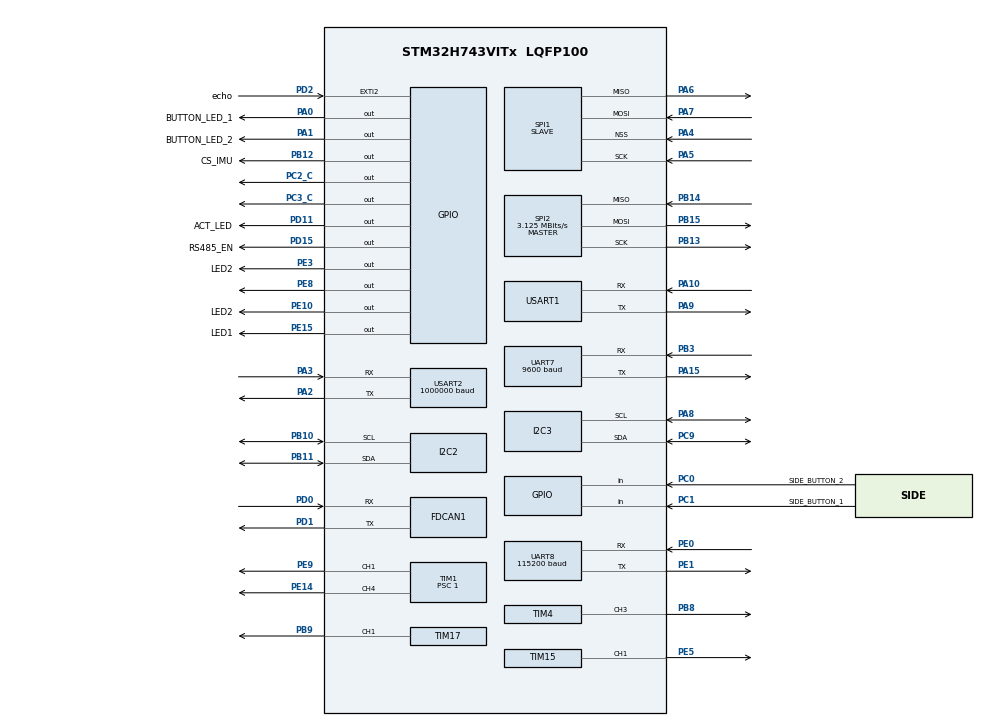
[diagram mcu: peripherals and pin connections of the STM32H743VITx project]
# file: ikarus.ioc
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CORTEX_M7.default_mode_Activation=0
Dma.MEMTOMEM.6.Direction=DMA_MEMORY_TO_MEMORY
Dma.MEMTOMEM.6.EventEnable=DISABLE
Dma.MEMTOMEM.6.FIFOMode=DMA_FIFOMODE_ENABLE
Dma.MEMTOMEM.6.FIFOThreshold=DMA_FIFO_THRESHOLD_FULL
Dma.MEMTOMEM.6.Instance=DMA2_Stream0
Dma.MEMTOMEM.6.MemBurst=DMA_MBURST_SINGLE
Dma.MEMTOMEM.6.MemDataAlignment=DMA_MDATAALIGN_BYTE
Dma.MEMTOMEM.6.MemInc=DMA_MINC_ENABLE
Dma.MEMTOMEM.6.Mode=DMA_NORMAL
Dma.MEMTOMEM.6.PeriphBurst=DMA_PBURST_SINGLE
Dma.MEMTOMEM.6.PeriphDataAlignment=DMA_PDATAALIGN_BYTE
Dma.MEMTOMEM.6.PeriphInc=DMA_PINC_ENABLE
Dma.MEMTOMEM.6.Polarity=HAL_DMAMUX_REQ_GEN_RISING
Dma.MEMTOMEM.6.Priority=DMA_PRIORITY_VERY_HIGH
Dma.MEMTOMEM.6.RequestNumber=1
Dma.MEMTOMEM.6.SignalID=NONE
Dma.MEMTOMEM.6.SyncEnable=DISABLE
Dma.MEMTOMEM.6.SyncPolarity=HAL_DMAMUX_SYNC_NO_EVENT
Dma.MEMTOMEM.6.SyncRequestNumber=1
Dma.MEMTOMEM.6.SyncSignalID=NONE
Dma.MEMTOMEM.9.Direction=DMA_MEMORY_TO_MEMORY
Dma.MEMTOMEM.9.EventEnable=DISABLE
Dma.MEMTOMEM.9.FIFOMode=DMA_FIFOMODE_ENABLE
Dma.MEMTOMEM.9.FIFOThreshold=DMA_FIFO_THRESHOLD_FULL
Dma.MEMTOMEM.9.Instance=DMA2_Stream1
Dma.MEMTOMEM.9.MemBurst=DMA_MBURST_SINGLE
Dma.MEMTOMEM.9.MemDataAlignment=DMA_MDATAALIGN_BYTE
Dma.MEMTOMEM.9.MemInc=DMA_MINC_ENABLE
Dma.MEMTOMEM.9.Mode=DMA_NORMAL
Dma.MEMTOMEM.9.PeriphBurst=DMA_PBURST_SINGLE
Dma.MEMTOMEM.9.PeriphDataAlignment=DMA_PDATAALIGN_BYTE
Dma.MEMTOMEM.9.PeriphInc=DMA_PINC_ENABLE
Dma.MEMTOMEM.9.Polarity=HAL_DMAMUX_REQ_GEN_RISING
Dma.MEMTOMEM.9.Priority=DMA_PRIORITY_HIGH
Dma.MEMTOMEM.9.RequestNumber=1
Dma.MEMTOMEM.9.SignalID=NONE
Dma.MEMTOMEM.9.SyncEnable=DISABLE
Dma.MEMTOMEM.9.SyncPolarity=HAL_DMAMUX_SYNC_NO_EVENT
Dma.MEMTOMEM.9.SyncRequestNumber=1
Dma.MEMTOMEM.9.SyncSignalID=NONE
Dma.Request0=USART1_RX
Dma.Request1=USART1_TX
Dma.Request10=UART7_RX
Dma.Request11=UART7_TX
Dma.Request12=TIM1_CH1
Dma.Request13=TIM1_CH4
Dma.Request14=TIM15_CH1
Dma.Request15=TIM4_CH3
Dma.Request2=UART8_RX
Dma.Request3=UART8_TX
Dma.Request4=USART2_RX
Dma.Request5=USART2_TX
Dma.Request6=MEMTOMEM
Dma.Request7=SPI1_RX
Dma.Request8=SPI1_TX
Dma.Request9=MEMTOMEM
Dma.SPI1_RX.7.Direction=DMA_PERIPH_TO_MEMORY
Dma.SPI1_RX.7.EventEnable=DISABLE
Dma.SPI1_RX.7.FIFOMode=DMA_FIFOMODE_DISABLE
Dma.SPI1_RX.7.Instance=DMA1_Stream6
Dma.SPI1_RX.7.MemDataAlignment=DMA_MDATAALIGN_BYTE
Dma.SPI1_RX.7.MemInc=DMA_MINC_ENABLE
Dma.SPI1_RX.7.Mode=DMA_NORMAL
Dma.SPI1_RX.7.PeriphDataAlignment=DMA_PDATAALIGN_BYTE
Dma.SPI1_RX.7.PeriphInc=DMA_PINC_DISABLE
Dma.SPI1_RX.7.Polarity=HAL_DMAMUX_REQ_GEN_RISING
Dma.SPI1_RX.7.Priority=DMA_PRIORITY_LOW
Dma.SPI1_RX.7.RequestNumber=1
Dma.SPI1_RX.7.SignalID=NONE
Dma.SPI1_RX.7.SyncEnable=DISABLE
Dma.SPI1_RX.7.SyncPolarity=HAL_DMAMUX_SYNC_NO_EVENT
Dma.SPI1_RX.7.SyncRequestNumber=1
Dma.SPI1_RX.7.SyncSignalID=NONE
Dma.SPI1_TX.8.Direction=DMA_MEMORY_TO_PERIPH
Dma.SPI1_TX.8.EventEnable=DISABLE
Dma.SPI1_TX.8.FIFOMode=DMA_FIFOMODE_DISABLE
Dma.SPI1_TX.8.Instance=DMA1_Stream7
Dma.SPI1_TX.8.MemDataAlignment=DMA_MDATAALIGN_BYTE
Dma.SPI1_TX.8.MemInc=DMA_MINC_ENABLE
Dma.SPI1_TX.8.Mode=DMA_NORMAL
Dma.SPI1_TX.8.PeriphDataAlignment=DMA_PDATAALIGN_BYTE
Dma.SPI1_TX.8.PeriphInc=DMA_PINC_DISABLE
Dma.SPI1_TX.8.Polarity=HAL_DMAMUX_REQ_GEN_RISING
Dma.SPI1_TX.8.Priority=DMA_PRIORITY_LOW
Dma.SPI1_TX.8.RequestNumber=1
Dma.SPI1_TX.8.SignalID=NONE
Dma.SPI1_TX.8.SyncEnable=DISABLE
Dma.SPI1_TX.8.SyncPolarity=HAL_DMAMUX_SYNC_NO_EVENT
Dma.SPI1_TX.8.SyncRequestNumber=1
Dma.SPI1_TX.8.SyncSignalID=NONE
Dma.TIM15_CH1.14.Direction=DMA_MEMORY_TO_PERIPH
Dma.TIM15_CH1.14.EventEnable=DISABLE
Dma.TIM15_CH1.14.FIFOMode=DMA_FIFOMODE_DISABLE
Dma.TIM15_CH1.14.Instance=DMA2_Stream6
Dma.TIM15_CH1.14.MemDataAlignment=DMA_MDATAALIGN_WORD
Dma.TIM15_CH1.14.MemInc=DMA_MINC_ENABLE
Dma.TIM15_CH1.14.Mode=DMA_NORMAL
Dma.TIM15_CH1.14.PeriphDataAlignment=DMA_PDATAALIGN_WORD
Dma.TIM15_CH1.14.PeriphInc=DMA_PINC_DISABLE
Dma.TIM15_CH1.14.Polarity=HAL_DMAMUX_REQ_GEN_RISING
Dma.TIM15_CH1.14.Priority=DMA_PRIORITY_LOW
Dma.TIM15_CH1.14.RequestNumber=1
Dma.TIM15_CH1.14.SignalID=NONE
Dma.TIM15_CH1.14.SyncEnable=DISABLE
Dma.TIM15_CH1.14.SyncPolarity=HAL_DMAMUX_SYNC_NO_EVENT
Dma.TIM15_CH1.14.SyncRequestNumber=1
Dma.TIM15_CH1.14.SyncSignalID=NONE
Dma.TIM1_CH1.12.Direction=DMA_MEMORY_TO_PERIPH
Dma.TIM1_CH1.12.EventEnable=DISABLE
Dma.TIM1_CH1.12.FIFOMode=DMA_FIFOMODE_DISABLE
Dma.TIM1_CH1.12.Instance=DMA2_Stream4
Dma.TIM1_CH1.12.MemDataAlignment=DMA_MDATAALIGN_WORD
Dma.TIM1_CH1.12.MemInc=DMA_MINC_ENABLE
Dma.TIM1_CH1.12.Mode=DMA_NORMAL
Dma.TIM1_CH1.12.PeriphDataAlignment=DMA_PDATAALIGN_WORD
Dma.TIM1_CH1.12.PeriphInc=DMA_PINC_DISABLE
Dma.TIM1_CH1.12.Polarity=HAL_DMAMUX_REQ_GEN_RISING
Dma.TIM1_CH1.12.Priority=DMA_PRIORITY_LOW
Dma.TIM1_CH1.12.RequestNumber=1
Dma.TIM1_CH1.12.SignalID=NONE
Dma.TIM1_CH1.12.SyncEnable=DISABLE
Dma.TIM1_CH1.12.SyncPolarity=HAL_DMAMUX_SYNC_NO_EVENT
Dma.TIM1_CH1.12.SyncRequestNumber=1
Dma.TIM1_CH1.12.SyncSignalID=NONE
Dma.TIM1_CH4.13.Direction=DMA_MEMORY_TO_PERIPH
Dma.TIM1_CH4.13.EventEnable=DISABLE
Dma.TIM1_CH4.13.FIFOMode=DMA_FIFOMODE_DISABLE
Dma.TIM1_CH4.13.Instance=DMA2_Stream5
Dma.TIM1_CH4.13.MemDataAlignment=DMA_MDATAALIGN_WORD
Dma.TIM1_CH4.13.MemInc=DMA_MINC_ENABLE
Dma.TIM1_CH4.13.Mode=DMA_NORMAL
Dma.TIM1_CH4.13.PeriphDataAlignment=DMA_PDATAALIGN_WORD
Dma.TIM1_CH4.13.PeriphInc=DMA_PINC_DISABLE
Dma.TIM1_CH4.13.Polarity=HAL_DMAMUX_REQ_GEN_RISING
Dma.TIM1_CH4.13.Priority=DMA_PRIORITY_LOW
Dma.TIM1_CH4.13.RequestNumber=1
Dma.TIM1_CH4.13.SignalID=NONE
Dma.TIM1_CH4.13.SyncEnable=DISABLE
Dma.TIM1_CH4.13.SyncPolarity=HAL_DMAMUX_SYNC_NO_EVENT
Dma.TIM1_CH4.13.SyncRequestNumber=1
Dma.TIM1_CH4.13.SyncSignalID=NONE
Dma.TIM4_CH3.15.Direction=DMA_MEMORY_TO_PERIPH
Dma.TIM4_CH3.15.EventEnable=DISABLE
Dma.TIM4_CH3.15.FIFOMode=DMA_FIFOMODE_DISABLE
Dma.TIM4_CH3.15.Instance=DMA2_Stream7
Dma.TIM4_CH3.15.MemDataAlignment=DMA_MDATAALIGN_WORD
Dma.TIM4_CH3.15.MemInc=DMA_MINC_ENABLE
Dma.TIM4_CH3.15.Mode=DMA_NORMAL
Dma.TIM4_CH3.15.PeriphDataAlignment=DMA_PDATAALIGN_WORD
Dma.TIM4_CH3.15.PeriphInc=DMA_PINC_DISABLE
Dma.TIM4_CH3.15.Polarity=HAL_DMAMUX_REQ_GEN_RISING
Dma.TIM4_CH3.15.Priority=DMA_PRIORITY_LOW
Dma.TIM4_CH3.15.RequestNumber=1
Dma.TIM4_CH3.15.SignalID=NONE
Dma.TIM4_CH3.15.SyncEnable=DISABLE
Dma.TIM4_CH3.15.SyncPolarity=HAL_DMAMUX_SYNC_NO_EVENT
Dma.TIM4_CH3.15.SyncRequestNumber=1
Dma.TIM4_CH3.15.SyncSignalID=NONE
Dma.UART7_RX.10.Direction=DMA_PERIPH_TO_MEMORY
Dma.UART7_RX.10.EventEnable=DISABLE
Dma.UART7_RX.10.FIFOMode=DMA_FIFOMODE_DISABLE
Dma.UART7_RX.10.Instance=DMA2_Stream2
Dma.UART7_RX.10.MemDataAlignment=DMA_MDATAALIGN_BYTE
Dma.UART7_RX.10.MemInc=DMA_MINC_ENABLE
Dma.UART7_RX.10.Mode=DMA_CIRCULAR
Dma.UART7_RX.10.PeriphDataAlignment=DMA_PDATAALIGN_BYTE
Dma.UART7_RX.10.PeriphInc=DMA_PINC_DISABLE
Dma.UART7_RX.10.Polarity=HAL_DMAMUX_REQ_GEN_RISING
Dma.UART7_RX.10.Priority=DMA_PRIORITY_LOW
Dma.UART7_RX.10.RequestNumber=1
Dma.UART7_RX.10.SignalID=NONE
Dma.UART7_RX.10.SyncEnable=DISABLE
Dma.UART7_RX.10.SyncPolarity=HAL_DMAMUX_SYNC_NO_EVENT
Dma.UART7_RX.10.SyncRequestNumber=1
Dma.UART7_RX.10.SyncSignalID=NONE
Dma.UART7_TX.11.Direction=DMA_MEMORY_TO_PERIPH
Dma.UART7_TX.11.EventEnable=DISABLE
Dma.UART7_TX.11.FIFOMode=DMA_FIFOMODE_DISABLE
Dma.UART7_TX.11.Instance=DMA2_Stream3
Dma.UART7_TX.11.MemDataAlignment=DMA_MDATAALIGN_BYTE
Dma.UART7_TX.11.MemInc=DMA_MINC_ENABLE
Dma.UART7_TX.11.Mode=DMA_NORMAL
Dma.UART7_TX.11.PeriphDataAlignment=DMA_PDATAALIGN_BYTE
Dma.UART7_TX.11.PeriphInc=DMA_PINC_DISABLE
Dma.UART7_TX.11.Polarity=HAL_DMAMUX_REQ_GEN_RISING
Dma.UART7_TX.11.Priority=DMA_PRIORITY_LOW
Dma.UART7_TX.11.RequestNumber=1
Dma.UART7_TX.11.SignalID=NONE
Dma.UART7_TX.11.SyncEnable=DISABLE
Dma.UART7_TX.11.SyncPolarity=HAL_DMAMUX_SYNC_NO_EVENT
Dma.UART7_TX.11.SyncRequestNumber=1
Dma.UART7_TX.11.SyncSignalID=NONE
Dma.UART8_RX.2.Direction=DMA_PERIPH_TO_MEMORY
Dma.UART8_RX.2.EventEnable=DISABLE
Dma.UART8_RX.2.FIFOMode=DMA_FIFOMODE_DISABLE
Dma.UART8_RX.2.Instance=DMA1_Stream2
Dma.UART8_RX.2.MemDataAlignment=DMA_MDATAALIGN_BYTE
Dma.UART8_RX.2.MemInc=DMA_MINC_ENABLE
Dma.UART8_RX.2.Mode=DMA_NORMAL
Dma.UART8_RX.2.PeriphDataAlignment=DMA_PDATAALIGN_BYTE
Dma.UART8_RX.2.PeriphInc=DMA_PINC_DISABLE
Dma.UART8_RX.2.Polarity=HAL_DMAMUX_REQ_GEN_RISING
Dma.UART8_RX.2.Priority=DMA_PRIORITY_HIGH
Dma.UART8_RX.2.RequestNumber=1
Dma.UART8_RX.2.SignalID=NONE
Dma.UART8_RX.2.SyncEnable=DISABLE
Dma.UART8_RX.2.SyncPolarity=HAL_DMAMUX_SYNC_NO_EVENT
Dma.UART8_RX.2.SyncRequestNumber=1
Dma.UART8_RX.2.SyncSignalID=NONE
Dma.UART8_TX.3.Direction=DMA_MEMORY_TO_PERIPH
Dma.UART8_TX.3.EventEnable=DISABLE
Dma.UART8_TX.3.FIFOMode=DMA_FIFOMODE_DISABLE
Dma.UART8_TX.3.Instance=DMA1_Stream3
Dma.UART8_TX.3.MemDataAlignment=DMA_MDATAALIGN_BYTE
Dma.UART8_TX.3.MemInc=DMA_MINC_ENABLE
Dma.UART8_TX.3.Mode=DMA_NORMAL
Dma.UART8_TX.3.PeriphDataAlignment=DMA_PDATAALIGN_BYTE
Dma.UART8_TX.3.PeriphInc=DMA_PINC_DISABLE
Dma.UART8_TX.3.Polarity=HAL_DMAMUX_REQ_GEN_RISING
Dma.UART8_TX.3.Priority=DMA_PRIORITY_LOW
Dma.UART8_TX.3.RequestNumber=1
Dma.UART8_TX.3.SignalID=NONE
Dma.UART8_TX.3.SyncEnable=DISABLE
Dma.UART8_TX.3.SyncPolarity=HAL_DMAMUX_SYNC_NO_EVENT
Dma.UART8_TX.3.SyncRequestNumber=1
Dma.UART8_TX.3.SyncSignalID=NONE
Dma.USART1_RX.0.Direction=DMA_PERIPH_TO_MEMORY
Dma.USART1_RX.0.EventEnable=DISABLE
Dma.USART1_RX.0.FIFOMode=DMA_FIFOMODE_DISABLE
Dma.USART1_RX.0.Instance=DMA1_Stream0
Dma.USART1_RX.0.MemDataAlignment=DMA_MDATAALIGN_BYTE
Dma.USART1_RX.0.MemInc=DMA_MINC_ENABLE
Dma.USART1_RX.0.Mode=DMA_NORMAL
Dma.USART1_RX.0.PeriphDataAlignment=DMA_PDATAALIGN_BYTE
Dma.USART1_RX.0.PeriphInc=DMA_PINC_DISABLE
Dma.USART1_RX.0.Polarity=HAL_DMAMUX_REQ_GEN_RISING
Dma.USART1_RX.0.Priority=DMA_PRIORITY_LOW
Dma.USART1_RX.0.RequestNumber=1
Dma.USART1_RX.0.SignalID=NONE
Dma.USART1_RX.0.SyncEnable=DISABLE
Dma.USART1_RX.0.SyncPolarity=HAL_DMAMUX_SYNC_NO_EVENT
Dma.USART1_RX.0.SyncRequestNumber=1
Dma.USART1_RX.0.SyncSignalID=NONE
Dma.USART1_TX.1.Direction=DMA_MEMORY_TO_PERIPH
Dma.USART1_TX.1.EventEnable=DISABLE
Dma.USART1_TX.1.FIFOMode=DMA_FIFOMODE_DISABLE
Dma.USART1_TX.1.Instance=DMA1_Stream1
Dma.USART1_TX.1.MemDataAlignment=DMA_MDATAALIGN_BYTE
Dma.USART1_TX.1.MemInc=DMA_MINC_ENABLE
Dma.USART1_TX.1.Mode=DMA_NORMAL
Dma.USART1_TX.1.PeriphDataAlignment=DMA_PDATAALIGN_BYTE
Dma.USART1_TX.1.PeriphInc=DMA_PINC_DISABLE
Dma.USART1_TX.1.Polarity=HAL_DMAMUX_REQ_GEN_RISING
Dma.USART1_TX.1.Priority=DMA_PRIORITY_LOW
Dma.USART1_TX.1.RequestNumber=1
Dma.USART1_TX.1.SignalID=NONE
Dma.USART1_TX.1.SyncEnable=DISABLE
Dma.USART1_TX.1.SyncPolarity=HAL_DMAMUX_SYNC_NO_EVENT
Dma.USART1_TX.1.SyncRequestNumber=1
Dma.USART1_TX.1.SyncSignalID=NONE
Dma.USART2_RX.4.Direction=DMA_PERIPH_TO_MEMORY
Dma.USART2_RX.4.EventEnable=DISABLE
Dma.USART2_RX.4.FIFOMode=DMA_FIFOMODE_DISABLE
Dma.USART2_RX.4.Instance=DMA1_Stream4
Dma.USART2_RX.4.MemDataAlignment=DMA_MDATAALIGN_BYTE
Dma.USART2_RX.4.MemInc=DMA_MINC_ENABLE
Dma.USART2_RX.4.Mode=DMA_NORMAL
Dma.USART2_RX.4.PeriphDataAlignment=DMA_PDATAALIGN_BYTE
Dma.USART2_RX.4.PeriphInc=DMA_PINC_DISABLE
Dma.USART2_RX.4.Polarity=HAL_DMAMUX_REQ_GEN_RISING
Dma.USART2_RX.4.Priority=DMA_PRIORITY_LOW
Dma.USART2_RX.4.RequestNumber=1
Dma.USART2_RX.4.SignalID=NONE
Dma.USART2_RX.4.SyncEnable=DISABLE
Dma.USART2_RX.4.SyncPolarity=HAL_DMAMUX_SYNC_NO_EVENT
Dma.USART2_RX.4.SyncRequestNumber=1
Dma.USART2_RX.4.SyncSignalID=NONE
Dma.USART2_TX.5.Direction=DMA_MEMORY_TO_PERIPH
Dma.USART2_TX.5.EventEnable=DISABLE
Dma.USART2_TX.5.FIFOMode=DMA_FIFOMODE_DISABLE
Dma.USART2_TX.5.Instance=DMA1_Stream5
Dma.USART2_TX.5.MemDataAlignment=DMA_MDATAALIGN_BYTE
Dma.USART2_TX.5.MemInc=DMA_MINC_ENABLE
Dma.USART2_TX.5.Mode=DMA_NORMAL
Dma.USART2_TX.5.PeriphDataAlignment=DMA_PDATAALIGN_BYTE
Dma.USART2_TX.5.PeriphInc=DMA_PINC_DISABLE
Dma.USART2_TX.5.Polarity=HAL_DMAMUX_REQ_GEN_RISING
Dma.USART2_TX.5.Priority=DMA_PRIORITY_LOW
Dma.USART2_TX.5.RequestNumber=1
Dma.USART2_TX.5.SignalID=NONE
Dma.USART2_TX.5.SyncEnable=DISABLE
Dma.USART2_TX.5.SyncPolarity=HAL_DMAMUX_SYNC_NO_EVENT
Dma.USART2_TX.5.SyncRequestNumber=1
Dma.USART2_TX.5.SyncSignalID=NONE
FDCAN1.CalculateBaudRateNominal=1000000
FDCAN1.CalculateTimeBitNominal=1000
FDCAN1.CalculateTimeQuantumNominal=100.0
FDCAN1.FrameFormat=FDCAN_FRAME_CLASSIC
FDCAN1.NominalPrescaler=10
FDCAN1.NominalTimeSeg1=7
FDCAN1.NominalTimeSeg2=2
FDCAN1.RxFifo0ElmtsNbr=4
FDCAN1.RxFifo1ElmtsNbr=4
FDCAN1.TxFifoQueueElmtsNbr=4
FREERTOS.Tasks01=defaultTask,24,128,StartDefaultTask,Default,NULL,Dynamic,NULL,NULL
FREERTOS.Timers01=myTimer02,Callback01,osTimerPeriodic,Default,NULL,Dynamic,NULL
FREERTOS.configTOTAL_HEAP_SIZE=120000
FREERTOS.configUSE_NEWLIB_REENTRANT=1
I2C2.Timing=0x10C0ECFF
I2C3.I2C_Rise_Time=0
I2C3.Timing=0x10C0ECFF
Mcu.Family=STM32H7
Mcu.Name=STM32H743VITx
Mcu.Package=LQFP100
NVIC.DMA1_Stream0_IRQn=true\:5\:0\:false\:false\:true\:true\:false\:true\:true
NVIC.DMA1_Stream1_IRQn=true\:5\:0\:false\:false\:true\:true\:false\:true\:true
NVIC.DMA1_Stream2_IRQn=true\:5\:0\:false\:false\:true\:false\:false\:true\:true
NVIC.DMA1_Stream3_IRQn=true\:5\:0\:false\:false\:true\:true\:false\:true\:true
NVIC.DMA1_Stream4_IRQn=true\:5\:0\:false\:false\:true\:true\:false\:true\:true
NVIC.DMA1_Stream5_IRQn=true\:5\:0\:false\:false\:true\:true\:false\:true\:true
NVIC.DMA1_Stream6_IRQn=true\:5\:0\:false\:false\:true\:true\:false\:true\:true
NVIC.DMA1_Stream7_IRQn=true\:5\:0\:false\:false\:true\:true\:false\:true\:true
NVIC.DMA2_Stream0_IRQn=true\:5\:0\:false\:false\:true\:true\:true\:true\:true
NVIC.DMA2_Stream1_IRQn=true\:5\:0\:false\:false\:true\:true\:true\:true\:true
NVIC.DMA2_Stream2_IRQn=true\:5\:0\:false\:false\:true\:true\:false\:true\:true
NVIC.DMA2_Stream3_IRQn=true\:5\:0\:false\:false\:true\:true\:false\:true\:true
NVIC.DMA2_Stream4_IRQn=true\:5\:0\:false\:false\:true\:true\:false\:true\:true
NVIC.DMA2_Stream5_IRQn=true\:5\:0\:false\:false\:true\:true\:false\:true\:true
NVIC.DMA2_Stream6_IRQn=true\:5\:0\:false\:false\:true\:true\:false\:true\:true
NVIC.DMA2_Stream7_IRQn=true\:5\:0\:false\:false\:true\:true\:false\:true\:true
NVIC.EXTI2_IRQn=true\:5\:0\:false\:false\:true\:true\:true\:true\:true
NVIC.FDCAN1_IT0_IRQn=true\:5\:0\:false\:false\:true\:true\:true\:true\:true
NVIC.FDCAN1_IT1_IRQn=true\:5\:0\:false\:false\:true\:true\:true\:true\:true
NVIC.I2C3_ER_IRQn=true\:5\:0\:false\:false\:true\:true\:true\:true\:true
NVIC.I2C3_EV_IRQn=true\:5\:0\:false\:false\:true\:true\:true\:true\:true
NVIC.PriorityGroup=NVIC_PRIORITYGROUP_4
NVIC.SPI1_IRQn=true\:5\:0\:false\:false\:true\:true\:true\:true\:true
NVIC.TIM17_IRQn=true\:5\:0\:false\:false\:true\:true\:true\:true\:true
NVIC.TIM1_BRK_IRQn=true\:5\:0\:false\:false\:true\:true\:true\:true\:true
NVIC.TIM1_CC_IRQn=true\:5\:0\:false\:false\:true\:true\:true\:true\:true
NVIC.TIM1_TRG_COM_IRQn=true\:5\:0\:false\:false\:true\:true\:true\:true\:true
NVIC.TIM1_UP_IRQn=true\:5\:0\:false\:false\:true\:true\:true\:true\:true
NVIC.TIM6_DAC_IRQn=true\:15\:0\:false\:false\:true\:false\:false\:true\:true
NVIC.TimeBase=TIM6_DAC_IRQn
NVIC.TimeBaseIP=TIM6
NVIC.UART7_IRQn=true\:5\:0\:false\:false\:true\:true\:true\:true\:true
NVIC.UART8_IRQn=true\:5\:0\:false\:false\:true\:true\:true\:true\:true
NVIC.USART1_IRQn=true\:5\:0\:false\:false\:true\:true\:true\:true\:true
NVIC.USART2_IRQn=true\:5\:0\:false\:false\:true\:true\:true\:true\:true
PA0.GPIO_Label=BUTTON_LED_1
PA0.Signal=GPIO_Output
PA1.GPIO_Label=BUTTON_LED_2
PA1.Signal=GPIO_Output
PA10.Mode=Asynchronous
PA10.Signal=USART1_RX
PA13\ (JTMS/SWDIO).Mode=Serial_Wire
PA13\ (JTMS/SWDIO).Signal=DEBUG_JTMS-SWDIO
PA14\ (JTCK/SWCLK).Mode=Serial_Wire
PA14\ (JTCK/SWCLK).Signal=DEBUG_JTCK-SWCLK
PA15\ (JTDI).Mode=Asynchronous
PA15\ (JTDI).Signal=UART7_TX
PA2.Mode=Asynchronous
PA2.Signal=USART2_TX
PA3.Mode=Asynchronous
PA3.Signal=USART2_RX
PA4.GPIO_PuPd=GPIO_NOPULL
PA4.GPIO_Speed=GPIO_SPEED_FREQ_VERY_HIGH
PA4.Mode=NSS_Signal_Hard_Input
PA4.Signal=SPI1_NSS
PA5.GPIO_Speed=GPIO_SPEED_FREQ_VERY_HIGH
PA5.Mode=Full_Duplex_Slave
PA5.Signal=SPI1_SCK
PA6.GPIO_Speed=GPIO_SPEED_FREQ_VERY_HIGH
PA6.Mode=Full_Duplex_Slave
PA6.Signal=SPI1_MISO
PA7.GPIO_Speed=GPIO_SPEED_FREQ_VERY_HIGH
PA7.Mode=Full_Duplex_Slave
PA7.Signal=SPI1_MOSI
PA8.Mode=I2C
PA8.Signal=I2C3_SCL
PA9.Mode=Asynchronous
PA9.Signal=USART1_TX
PB10.Mode=I2C
PB10.Signal=I2C2_SCL
PB11.Mode=I2C
PB11.Signal=I2C2_SDA
PB12.GPIO_Label=CS_IMU
PB12.Signal=GPIO_Output
PB13.Mode=Full_Duplex_Master
PB13.Signal=SPI2_SCK
PB14.Mode=Full_Duplex_Master
PB14.Signal=SPI2_MISO
PB15.Mode=Full_Duplex_Master
PB15.Signal=SPI2_MOSI
PB3\ (JTDO/TRACESWO).Mode=Asynchronous
PB3\ (JTDO/TRACESWO).Signal=UART7_RX
PB8.Signal=S_TIM4_CH3
PB9.Signal=S_TIM17_CH1
PC0.GPIO_Label=SIDE_BUTTON_2
PC0.GPIO_PuPd=GPIO_PULLUP
PC0.Signal=GPIO_Input
PC1.GPIO_Label=SIDE_BUTTON_1
PC1.GPIO_PuPd=GPIO_PULLUP
PC1.Signal=GPIO_Input
PC2_C.Signal=GPIO_Output
PC3_C.Signal=GPIO_Output
PC9.Mode=I2C
PC9.Signal=I2C3_SDA
PD0.Mode=FDCAN_Activate
PD0.Signal=FDCAN1_RX
PD1.Mode=FDCAN_Activate
PD1.Signal=FDCAN1_TX
PD11.GPIO_Label=ACT_LED
PD11.Signal=GPIO_Output
PD15.GPIO_Label=RS485_EN
PD15.Signal=GPIO_Output
PD2.GPIO_Label=echo
PD2.GPIO_ModeDefaultEXTI=GPIO_MODE_IT_RISING_FALLING
PD2.Signal=GPXTI2
PE0.Mode=Asynchronous
PE0.Signal=UART8_RX
PE1.Mode=Asynchronous
PE1.Signal=UART8_TX
PE10.GPIO_Label=LED2
PE10.Signal=GPIO_Output
PE14.Signal=S_TIM1_CH4
PE15.GPIO_Label=LED1
PE15.Signal=GPIO_Output
PE3.GPIO_Label=LED2
PE3.Signal=GPIO_Output
PE5.Signal=S_TIM15_CH1
PE8.Signal=GPIO_Output
PE9.Signal=S_TIM1_CH1
PH0-OSC_IN\ (PH0).Mode=HSE-External-Oscillator
PH0-OSC_IN\ (PH0).Signal=RCC_OSC_IN
PH1-OSC_OUT\ (PH1).Mode=HSE-External-Oscillator
PH1-OSC_OUT\ (PH1).Signal=RCC_OSC_OUT
ProjectManager.HeapSize=0x200
ProjectManager.StackSize=0x400
ProjectManager.TargetToolchain=STM32CubeIDE
RCC.ADCFreq_Value=100000000
RCC.APB1Freq_Value=100000000
RCC.APB2Freq_Value=100000000
RCC.APB3Freq_Value=100000000
RCC.APB4Freq_Value=100000000
RCC.CortexFreq_Value=400000000
RCC.D1PPRE=RCC_APB3_DIV2
RCC.D2PPRE1=RCC_APB1_DIV2
RCC.D2PPRE2=RCC_APB2_DIV2
RCC.D3PPRE=RCC_APB4_DIV2
RCC.DIVM1=2
RCC.DIVM2=2
RCC.DIVN1=64
RCC.DIVN2=64
RCC.DIVP2=8
RCC.DIVQ1=4
RCC.DIVQ2=8
RCC.FDCANCLockSelection=RCC_FDCANCLKSOURCE_PLL2
RCC.HCLKFreq_Value=200000000
RCC.HPRE=RCC_HCLK_DIV2
RCC.PLL2FRACN=0
RCC.PLLFRACN=0
RCC.PLLSourceVirtual=RCC_PLLSOURCE_HSE
RCC.PWR_Regulator_Voltage_Scale=PWR_REGULATOR_VOLTAGE_SCALE0
RCC.SYSCLKFreq_VALUE=400000000
RCC.SYSCLKSource=RCC_SYSCLKSOURCE_PLLCLK
RCC.USBFreq_Value=200000000
SH.S_TIM15_CH1.0=TIM15_CH1,PWM Generation1 CH1
SH.S_TIM17_CH1.0=TIM17_CH1,PWM Generation1 CH1
SH.S_TIM1_CH1.0=TIM1_CH1,PWM Generation1 CH1
SH.S_TIM1_CH4.0=TIM1_CH4,PWM Generation4 CH4
SH.S_TIM4_CH3.0=TIM4_CH3,PWM Generation3 CH3
SPI1.DataSize=SPI_DATASIZE_8BIT
SPI1.Direction=SPI_DIRECTION_2LINES
SPI1.Mode=SPI_MODE_SLAVE
SPI1.VirtualNSS=VM_NSSHARD
SPI1.VirtualType=VM_SLAVE
SPI2.BaudRatePrescaler=SPI_BAUDRATEPRESCALER_64
SPI2.CalculateBaudRate=3.125 MBits/s
SPI2.DataSize=SPI_DATASIZE_8BIT
SPI2.Direction=SPI_DIRECTION_2LINES
SPI2.Mode=SPI_MODE_MASTER
SPI2.VirtualType=VM_MASTER
TIM1.Channel-PWM\ Generation1\ CH1=TIM_CHANNEL_1
TIM1.Channel-PWM\ Generation4\ CH4=TIM_CHANNEL_4
TIM1.Period=331
TIM1.Prescaler=1
TIM15.Channel-PWM\ Generation1\ CH1=TIM_CHANNEL_1
TIM15.Period=331
TIM15.Prescaler=1
TIM16.Prescaler=200-1
TIM17.Channel=TIM_CHANNEL_1
TIM17.Period=9999
TIM17.Prescaler=999
TIM4.Channel-PWM\ Generation3\ CH3=TIM_CHANNEL_3
TIM4.Period=331
TIM4.Prescaler=1
UART7.BaudRate=9600
UART8.BaudRate=115200
UART8.Parity=PARITY_EVEN
UART8.WordLength=WORDLENGTH_9B
USART1.VirtualMode-Asynchronous=VM_ASYNC
USART2.BaudRate=1000000
USART2.VirtualMode-Asynchronous=VM_ASYNC
VP_FREERTOS_VS_CMSIS_V2.Mode=CMSIS_V2
VP_MEMORYMAP_VS_MEMORYMAP.Mode=CurAppReg
VP_SYS_VS_tim6.Mode=TIM6
VP_TIM16_VS_ClockSourceINT.Mode=Enable_Timer
VP_TIM17_VS_ClockSourceINT.Mode=Enable_Timer
VP_TIM2_VS_ClockSourceINT.Mode=Internal
board=custom

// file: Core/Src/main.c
/* USER CODE BEGIN Header */
/**
  ******************************************************************************
  * @file           : main.c
  * @brief          : Main program body
  ******************************************************************************
  * @attention
  *
  * Copyright (c) 2025 STMicroelectronics.
  * All rights reserved.
  *
  * This software is licensed under terms that can be found in the LICENSE file
  * in the root directory of this software component.
  * If no LICENSE file comes with this software, it is provided AS-IS.
  *
  ******************************************************************************
  */
/* USER CODE END Header */
#include "main.h"
#include "cmsis_os.h"
#include "dma.h"
#include "fdcan.h"
#include "i2c.h"
#include "spi.h"
#include "tim.h"
#include "usart.h"
#include "gpio.h"

void SystemClock_Config(void);
void MX_FREERTOS_Init(void);

int main(void)
{

  /* MCU Configuration--------------------------------------------------------*/

  /* Reset of all peripherals, Initializes the Flash interface and the Systick. */
  HAL_Init();

  /* Configure the system clock */
  SystemClock_Config();

  /* Initialize all configured peripherals */
  MX_GPIO_Init();
  MX_DMA_Init();
  MX_USART1_UART_Init();
  MX_SPI2_Init();
  MX_UART8_Init();
  MX_USART2_UART_Init();
  MX_TIM2_Init();
  MX_SPI1_Init();
  MX_I2C3_Init();
  MX_FDCAN1_Init();
  MX_TIM1_Init();
  MX_TIM15_Init();
  MX_UART7_Init();
  MX_I2C2_Init();
  MX_TIM4_Init();
  MX_TIM17_Init();
  MX_TIM16_Init();

  /* Init scheduler */
  osKernelInitialize();  /* Call init function for freertos objects (in cmsis_os2.c) */
  MX_FREERTOS_Init();

  /* Start scheduler */
  osKernelStart();

  /* We should never get here as control is now taken by the scheduler */

  /* Infinite loop */
  while (1)
  {

  }
}

void SystemClock_Config(void)
{
  RCC_OscInitTypeDef RCC_OscInitStruct = {0};
  RCC_ClkInitTypeDef RCC_ClkInitStruct = {0};

  /** Supply configuration update enable
  */
  HAL_PWREx_ConfigSupply(PWR_LDO_SUPPLY);

  /** Configure the main internal regulator output voltage
  */
  __HAL_PWR_VOLTAGESCALING_CONFIG(PWR_REGULATOR_VOLTAGE_SCALE0);

  while(!__HAL_PWR_GET_FLAG(PWR_FLAG_VOSRDY)) {}

  /** Initializes the RCC Oscillators according to the specified parameters
  * in the RCC_OscInitTypeDef structure.
  */
  RCC_OscInitStruct.OscillatorType = RCC_OSCILLATORTYPE_HSE;
  RCC_OscInitStruct.HSEState = RCC_HSE_ON;
  RCC_OscInitStruct.PLL.PLLState = RCC_PLL_ON;
  RCC_OscInitStruct.PLL.PLLSource = RCC_PLLSOURCE_HSE;
  RCC_OscInitStruct.PLL.PLLM = 2;
  RCC_OscInitStruct.PLL.PLLN = 64;
  RCC_OscInitStruct.PLL.PLLP = 2;
  RCC_OscInitStruct.PLL.PLLQ = 4;
  RCC_OscInitStruct.PLL.PLLR = 2;
  RCC_OscInitStruct.PLL.PLLRGE = RCC_PLL1VCIRANGE_3;
  RCC_OscInitStruct.PLL.PLLVCOSEL = RCC_PLL1VCOWIDE;
  RCC_OscInitStruct.PLL.PLLFRACN = 0;
  if (HAL_RCC_OscConfig(&RCC_OscInitStruct) != HAL_OK)
  {
    Error_Handler();
  }

  /** Initializes the CPU, AHB and APB buses clocks
  */
  RCC_ClkInitStruct.ClockType = RCC_CLOCKTYPE_HCLK|RCC_CLOCKTYPE_SYSCLK
                              |RCC_CLOCKTYPE_PCLK1|RCC_CLOCKTYPE_PCLK2
                              |RCC_CLOCKTYPE_D3PCLK1|RCC_CLOCKTYPE_D1PCLK1;
  RCC_ClkInitStruct.SYSCLKSource = RCC_SYSCLKSOURCE_PLLCLK;
  RCC_ClkInitStruct.SYSCLKDivider = RCC_SYSCLK_DIV1;
  RCC_ClkInitStruct.AHBCLKDivider = RCC_HCLK_DIV2;
  RCC_ClkInitStruct.APB3CLKDivider = RCC_APB3_DIV2;
  RCC_ClkInitStruct.APB1CLKDivider = RCC_APB1_DIV2;
  RCC_ClkInitStruct.APB2CLKDivider = RCC_APB2_DIV2;
  RCC_ClkInitStruct.APB4CLKDivider = RCC_APB4_DIV2;

  if (HAL_RCC_ClockConfig(&RCC_ClkInitStruct, FLASH_LATENCY_2) != HAL_OK)
  {
    Error_Handler();
  }
}

void HAL_TIM_PeriodElapsedCallback(TIM_HandleTypeDef *htim)
{
  if (htim->Instance == TIM6)
  {
    HAL_IncTick();
  }
}

void Error_Handler(void)
{
  __disable_irq();
  while (1)
  {
  }
}

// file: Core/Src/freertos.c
/* USER CODE BEGIN Header */
/**
  ******************************************************************************
  * File Name          : freertos.c
  * Description        : Code for freertos applications
  ******************************************************************************
  * @attention
  *
  * Copyright (c) 2025 STMicroelectronics.
  * All rights reserved.
  *
  * This software is licensed under terms that can be found in the LICENSE file
  * in the root directory of this software component.
  * If no LICENSE file comes with this software, it is provided AS-IS.
  *
  ******************************************************************************
  */
/* USER CODE END Header */

#include "FreeRTOS.h"
#include "task.h"
#include "main.h"
#include "cmsis_os.h"

/* Definitions for defaultTask */
osThreadId_t defaultTaskHandle;
const osThreadAttr_t defaultTask_attributes = {
  .name = "defaultTask",
  .stack_size = 128 * 4,
  .priority = (osPriority_t) osPriorityNormal,
};
/* Definitions for myTimer02 */
osTimerId_t myTimer02Handle;
const osTimerAttr_t myTimer02_attributes = {
  .name = "myTimer02"
};

void StartDefaultTask(void *argument);
void Callback01(void *argument);

void MX_FREERTOS_Init(void); /* (MISRA C 2004 rule 8.1) */

void MX_FREERTOS_Init(void) {

  /* Create the timer(s) */
  /* creation of myTimer02 */
  myTimer02Handle = osTimerNew(Callback01, osTimerPeriodic, NULL, &myTimer02_attributes);

  /* Create the thread(s) */
  /* creation of defaultTask */
  defaultTaskHandle = osThreadNew(StartDefaultTask, NULL, &defaultTask_attributes);

  /* USER CODE BEGIN RTOS_THREADS */
  /* add threads, ... */
  firmware();
  /* USER CODE END RTOS_THREADS */

}

void StartDefaultTask(void *argument)
{
  /* USER CODE BEGIN StartDefaultTask */
  /* Infinite loop */
	osDelay(1000);
    vTaskDelete(NULL); //stop task because right now it is not needed anymore

  for(;;)
  {
    osDelay(1);
  }
  /* USER CODE END StartDefaultTask */
}

/* Callback01 function */
void Callback01(void *argument)
{
}
